# STC32G144K246 register map
Vendor: STC; File version: 2.0
Registers are 8-bit, read-write, no defined reset value unless marked. A register's access mark holds for its fields unless they carry their own. Offsets are from the block's base; [hi:lo] are bit positions; {n}, {i} and the like mark numbered series.

## GPIO1 — P1 端口、模式、上下拉和中断
Base 0x007EFD01
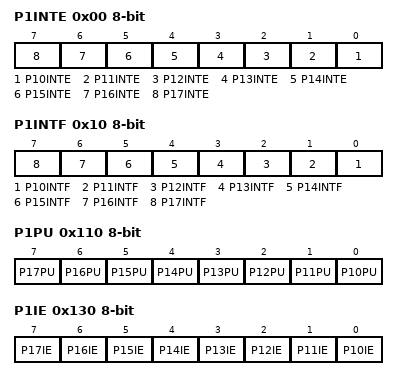
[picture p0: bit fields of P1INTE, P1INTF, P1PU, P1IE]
0x00 P1INTE — P1口中断使能寄存器
  [n-10] P{n}INTE (n=10..17) — 尚未自动匹配到此字段的独立说明；请查看下方章节说明。
0x10 P1INTF ro — P1口中断标志寄存器
  [n-10] P{n}INTF (n=10..17) — 尚未自动匹配到此字段的独立说明；请查看下方章节说明。
0x110 P1PU — P1口上拉电阻控制寄存器
  [all] fields
    0=禁止内部上拉电阻; 1=使能内部上拉电阻
  [7] P17PU — 控制 P1.7 的内部上拉电阻。
  [6] P16PU — 控制 P1.6 的内部上拉电阻。
  [5] P15PU — 控制 P1.5 的内部上拉电阻。
  [4] P14PU — 控制 P1.4 的内部上拉电阻。
  [3] P13PU — 控制 P1.3 的内部上拉电阻。
  [2] P12PU — 控制 P1.2 的内部上拉电阻。
  [1] P11PU — 控制 P1.1 的内部上拉电阻。
  [0] P10PU — 控制 P1.0 的内部上拉电阻。
0x130 P1IE — P1口输入使能控制寄存器
  [all] fields
    0=禁止数字信号输入，用于模拟功能; 1=使能数字信号输入
  [7] P17IE — 控制 P1.7 的数字信号输入。
  [6] P16IE — 控制 P1.6 的数字信号输入。
  [5] P15IE — 控制 P1.5 的数字信号输入。
  [4] P14IE — 控制 P1.4 的数字信号输入。
  [3] P13IE — 控制 P1.3 的数字信号输入。
  [2] P12IE — 控制 P1.2 的数字信号输入。
  [1] P11IE — 控制 P1.1 的数字信号输入。
  [0] P10IE — 控制 P1.0 的数字信号输入。
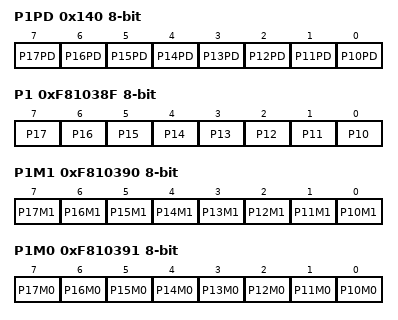
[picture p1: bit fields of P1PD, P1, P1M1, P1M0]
0x140 P1PD — P1口下拉电阻控制寄存器
  [all] fields
    0=禁止内部下拉电阻; 1=使能内部下拉电阻
  [7] P17PD — 控制 P1.7 的内部下拉电阻。
  [6] P16PD — 控制 P1.6 的内部下拉电阻。
  [5] P15PD — 控制 P1.5 的内部下拉电阻。
  [4] P14PD — 控制 P1.4 的内部下拉电阻。
  [3] P13PD — 控制 P1.3 的内部下拉电阻。
  [2] P12PD — 控制 P1.2 的内部下拉电阻。
  [1] P11PD — 控制 P1.1 的内部下拉电阻。
  [0] P10PD — 控制 P1.0 的内部下拉电阻。
0xF81038F P1 — P1端口
  [all] fields
    0=低电平; 1=高电平
  [7] P17 — 读取 P1.7 管脚电平；写入 P1.7 的输出缓冲区。实际输出行为由端口模式及外设复用共同决定。
  [6] P16 — 读取 P1.6 管脚电平；写入 P1.6 的输出缓冲区。实际输出行为由端口模式及外设复用共同决定。
  [5] P15 — 读取 P1.5 管脚电平；写入 P1.5 的输出缓冲区。实际输出行为由端口模式及外设复用共同决定。
  [4] P14 — 读取 P1.4 管脚电平；写入 P1.4 的输出缓冲区。实际输出行为由端口模式及外设复用共同决定。
  [3] P13 — 读取 P1.3 管脚电平；写入 P1.3 的输出缓冲区。实际输出行为由端口模式及外设复用共同决定。
  [2] P12 — 读取 P1.2 管脚电平；写入 P1.2 的输出缓冲区。实际输出行为由端口模式及外设复用共同决定。
  [1] P11 — 读取 P1.1 管脚电平；写入 P1.1 的输出缓冲区。实际输出行为由端口模式及外设复用共同决定。
  [0] P10 — 读取 P1.0 管脚电平；写入 P1.0 的输出缓冲区。实际输出行为由端口模式及外设复用共同决定。
0xF810390 P1M1 — P1口配置寄存器1
  [7] P17M1 — 控制 P1.7 的端口模式高位；与 P1M0.B7 配合设置，组合含义见下表。
  [6] P16M1 — 控制 P1.6 的端口模式高位；与 P1M0.B6 配合设置，组合含义见下表。
  [5] P15M1 — 控制 P1.5 的端口模式高位；与 P1M0.B5 配合设置，组合含义见下表。
  [4] P14M1 — 控制 P1.4 的端口模式高位；与 P1M0.B4 配合设置，组合含义见下表。
  [3] P13M1 — 控制 P1.3 的端口模式高位；与 P1M0.B3 配合设置，组合含义见下表。
  [2] P12M1 — 控制 P1.2 的端口模式高位；与 P1M0.B2 配合设置，组合含义见下表。
  [1] P11M1 — 控制 P1.1 的端口模式高位；与 P1M0.B1 配合设置，组合含义见下表。
  [0] P10M1 — 控制 P1.0 的端口模式高位；与 P1M0.B0 配合设置，组合含义见下表。
0xF810391 P1M0 — P1口配置寄存器0
  [7] P17M0 — 控制 P1.7 的端口模式低位；与 P1M1.B7 配合设置，组合含义见下表。
  [6] P16M0 — 控制 P1.6 的端口模式低位；与 P1M1.B6 配合设置，组合含义见下表。
  [5] P15M0 — 控制 P1.5 的端口模式低位；与 P1M1.B5 配合设置，组合含义见下表。
  [4] P14M0 — 控制 P1.4 的端口模式低位；与 P1M1.B4 配合设置，组合含义见下表。
  [3] P13M0 — 控制 P1.3 的端口模式低位；与 P1M1.B3 配合设置，组合含义见下表。
  [2] P12M0 — 控制 P1.2 的端口模式低位；与 P1M1.B2 配合设置，组合含义见下表。
  [1] P11M0 — 控制 P1.1 的端口模式低位；与 P1M1.B1 配合设置，组合含义见下表。
  [0] P10M0 — 控制 P1.0 的端口模式低位；与 P1M1.B0 配合设置，组合含义见下表。

## GPIO2 — P2 端口、模式、上下拉和中断
Base 0x007EFD02
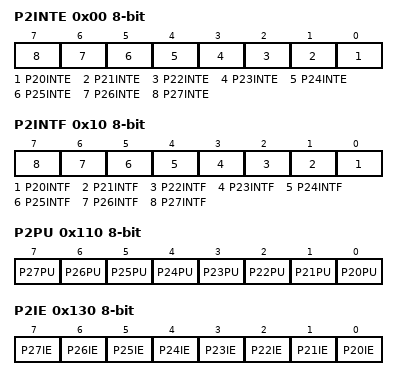
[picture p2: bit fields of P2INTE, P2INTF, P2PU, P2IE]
0x00 P2INTE — P2口中断使能寄存器
  [n-20] P{n}INTE (n=20..27) — 尚未自动匹配到此字段的独立说明；请查看下方章节说明。
0x10 P2INTF ro — P2口中断标志寄存器
  [n-20] P{n}INTF (n=20..27) — 尚未自动匹配到此字段的独立说明；请查看下方章节说明。
0x110 P2PU — P2口上拉电阻控制寄存器
  [all] fields
    0=禁止内部上拉电阻; 1=使能内部上拉电阻
  [7] P27PU — 控制 P2.7 的内部上拉电阻。
  [6] P26PU — 控制 P2.6 的内部上拉电阻。
  [5] P25PU — 控制 P2.5 的内部上拉电阻。
  [4] P24PU — 控制 P2.4 的内部上拉电阻。
  [3] P23PU — 控制 P2.3 的内部上拉电阻。
  [2] P22PU — 控制 P2.2 的内部上拉电阻。
  [1] P21PU — 控制 P2.1 的内部上拉电阻。
  [0] P20PU — 控制 P2.0 的内部上拉电阻。
0x130 P2IE — P2口输入使能控制寄存器
  [all] fields
    0=禁止数字信号输入，用于模拟功能; 1=使能数字信号输入
  [7] P27IE — 控制 P2.7 的数字信号输入。
  [6] P26IE — 控制 P2.6 的数字信号输入。
  [5] P25IE — 控制 P2.5 的数字信号输入。
  [4] P24IE — 控制 P2.4 的数字信号输入。
  [3] P23IE — 控制 P2.3 的数字信号输入。
  [2] P22IE — 控制 P2.2 的数字信号输入。
  [1] P21IE — 控制 P2.1 的数字信号输入。
  [0] P20IE — 控制 P2.0 的数字信号输入。
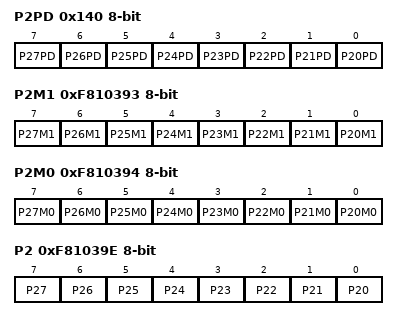
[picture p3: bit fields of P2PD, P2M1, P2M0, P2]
0x140 P2PD — P2口下拉电阻控制寄存器
  [all] fields
    0=禁止内部下拉电阻; 1=使能内部下拉电阻
  [7] P27PD — 控制 P2.7 的内部下拉电阻。
  [6] P26PD — 控制 P2.6 的内部下拉电阻。
  [5] P25PD — 控制 P2.5 的内部下拉电阻。
  [4] P24PD — 控制 P2.4 的内部下拉电阻。
  [3] P23PD — 控制 P2.3 的内部下拉电阻。
  [2] P22PD — 控制 P2.2 的内部下拉电阻。
  [1] P21PD — 控制 P2.1 的内部下拉电阻。
  [0] P20PD — 控制 P2.0 的内部下拉电阻。
0xF810393 P2M1 — P2口配置寄存器1
  [7] P27M1 — 控制 P2.7 的端口模式高位；与 P2M0.B7 配合设置，组合含义见下表。
  [6] P26M1 — 控制 P2.6 的端口模式高位；与 P2M0.B6 配合设置，组合含义见下表。
  [5] P25M1 — 控制 P2.5 的端口模式高位；与 P2M0.B5 配合设置，组合含义见下表。
  [4] P24M1 — 控制 P2.4 的端口模式高位；与 P2M0.B4 配合设置，组合含义见下表。
  [3] P23M1 — 控制 P2.3 的端口模式高位；与 P2M0.B3 配合设置，组合含义见下表。
  [2] P22M1 — 控制 P2.2 的端口模式高位；与 P2M0.B2 配合设置，组合含义见下表。
  [1] P21M1 — 控制 P2.1 的端口模式高位；与 P2M0.B1 配合设置，组合含义见下表。
  [0] P20M1 — 控制 P2.0 的端口模式高位；与 P2M0.B0 配合设置，组合含义见下表。
0xF810394 P2M0 — P2口配置寄存器0
  [7] P27M0 — 控制 P2.7 的端口模式低位；与 P2M1.B7 配合设置，组合含义见下表。
  [6] P26M0 — 控制 P2.6 的端口模式低位；与 P2M1.B6 配合设置，组合含义见下表。
  [5] P25M0 — 控制 P2.5 的端口模式低位；与 P2M1.B5 配合设置，组合含义见下表。
  [4] P24M0 — 控制 P2.4 的端口模式低位；与 P2M1.B4 配合设置，组合含义见下表。
  [3] P23M0 — 控制 P2.3 的端口模式低位；与 P2M1.B3 配合设置，组合含义见下表。
  [2] P22M0 — 控制 P2.2 的端口模式低位；与 P2M1.B2 配合设置，组合含义见下表。
  [1] P21M0 — 控制 P2.1 的端口模式低位；与 P2M1.B1 配合设置，组合含义见下表。
  [0] P20M0 — 控制 P2.0 的端口模式低位；与 P2M1.B0 配合设置，组合含义见下表。
0xF81039E P2 — P2端口
  [all] fields
    0=低电平; 1=高电平
  [7] P27 — 读取 P2.7 管脚电平；写入 P2.7 的输出缓冲区。实际输出行为由端口模式及外设复用共同决定。
  [6] P26 — 读取 P2.6 管脚电平；写入 P2.6 的输出缓冲区。实际输出行为由端口模式及外设复用共同决定。
  [5] P25 — 读取 P2.5 管脚电平；写入 P2.5 的输出缓冲区。实际输出行为由端口模式及外设复用共同决定。
  [4] P24 — 读取 P2.4 管脚电平；写入 P2.4 的输出缓冲区。实际输出行为由端口模式及外设复用共同决定。
  [3] P23 — 读取 P2.3 管脚电平；写入 P2.3 的输出缓冲区。实际输出行为由端口模式及外设复用共同决定。
  [2] P22 — 读取 P2.2 管脚电平；写入 P2.2 的输出缓冲区。实际输出行为由端口模式及外设复用共同决定。
  [1] P21 — 读取 P2.1 管脚电平；写入 P2.1 的输出缓冲区。实际输出行为由端口模式及外设复用共同决定。
  [0] P20 — 读取 P2.0 管脚电平；写入 P2.0 的输出缓冲区。实际输出行为由端口模式及外设复用共同决定。
